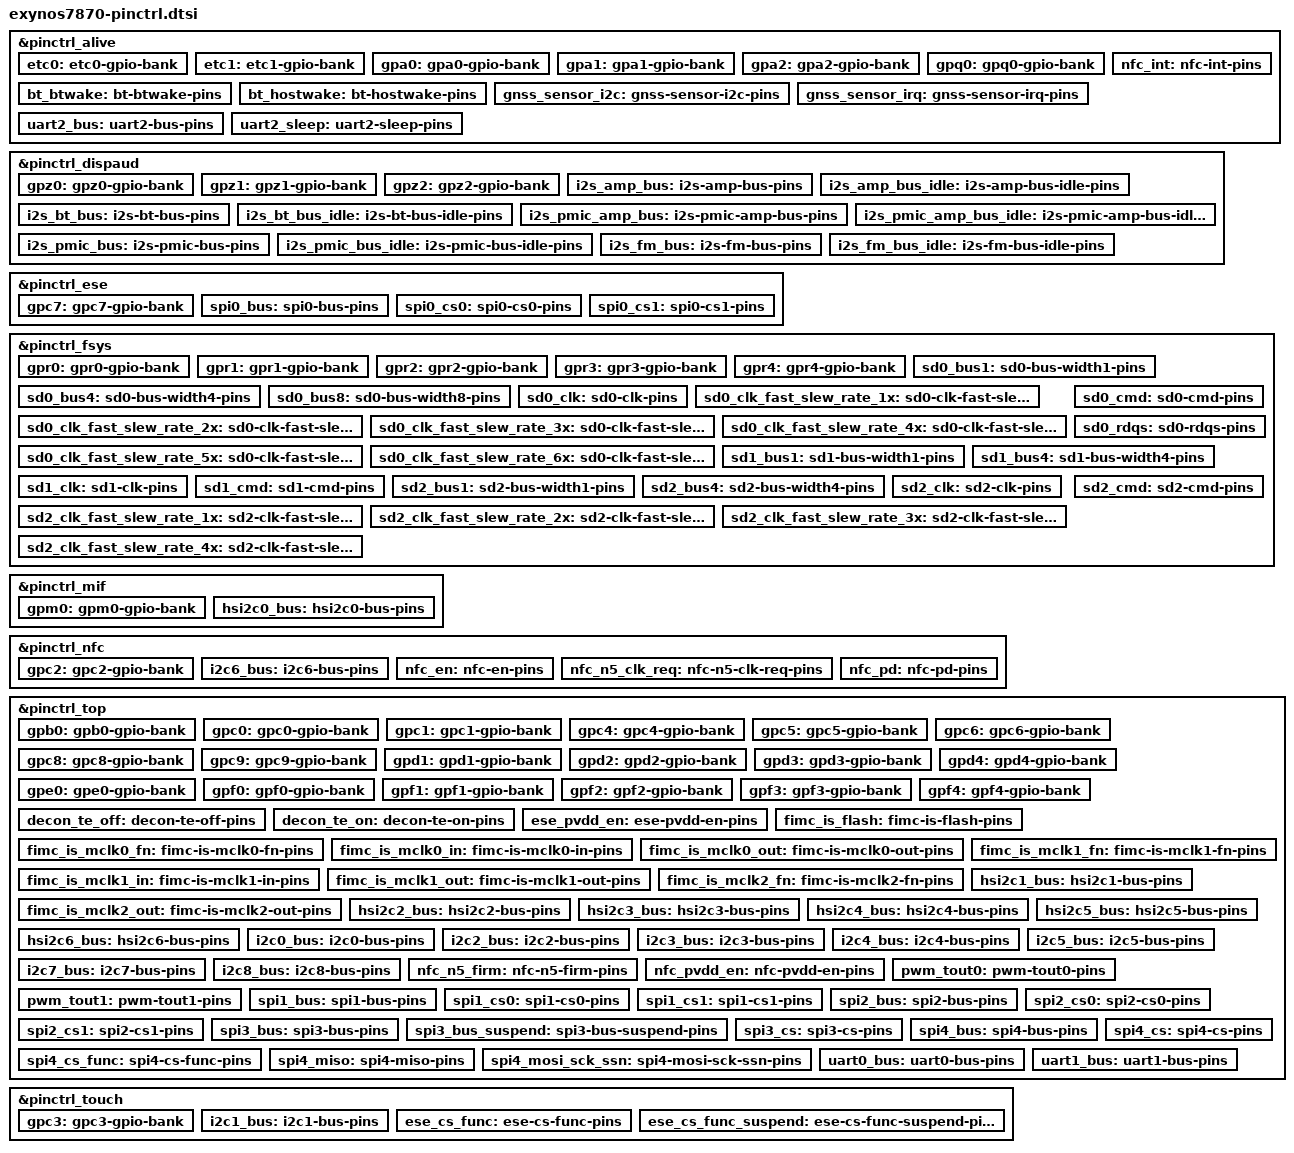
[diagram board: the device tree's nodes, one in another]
// SPDX-License-Identifier: GPL-2.0
/*
 * Samsung Exynos7870 SoC pin-mux and pin-config device tree source
 *
 * Copyright (c) 2015 Samsung Electronics Co., Ltd.
 * Copyright (c) 2025 Kaustabh Chakraborty <kauschluss@disroot.org>
 */

#include <dt-bindings/interrupt-controller/arm-gic.h>
#include "exynos-pinctrl.h"

&pinctrl_alive {
	etc0: etc0-gpio-bank {
		gpio-controller;
		#gpio-cells = <2>;

		interrupt-controller;
		#interrupt-cells = <2>;
	};

	etc1: etc1-gpio-bank {
		gpio-controller;
		#gpio-cells = <2>;

		interrupt-controller;
		#interrupt-cells = <2>;
	};

	gpa0: gpa0-gpio-bank {
		gpio-controller;
		#gpio-cells = <2>;

		interrupt-controller;
		#interrupt-cells = <2>;
		interrupt-parent = <&gic>;
		interrupts = <GIC_SPI 0 IRQ_TYPE_LEVEL_HIGH>,
			     <GIC_SPI 1 IRQ_TYPE_LEVEL_HIGH>,
			     <GIC_SPI 2 IRQ_TYPE_LEVEL_HIGH>,
			     <GIC_SPI 3 IRQ_TYPE_LEVEL_HIGH>,
			     <GIC_SPI 4 IRQ_TYPE_LEVEL_HIGH>,
			     <GIC_SPI 5 IRQ_TYPE_LEVEL_HIGH>,
			     <GIC_SPI 6 IRQ_TYPE_LEVEL_HIGH>,
			     <GIC_SPI 7 IRQ_TYPE_LEVEL_HIGH>;
	};

	gpa1: gpa1-gpio-bank {
		gpio-controller;
		#gpio-cells = <2>;

		interrupt-controller;
		#interrupt-cells = <2>;
		interrupt-parent = <&gic>;
		interrupts = <GIC_SPI 8 IRQ_TYPE_LEVEL_HIGH>,
			     <GIC_SPI 9 IRQ_TYPE_LEVEL_HIGH>,
			     <GIC_SPI 10 IRQ_TYPE_LEVEL_HIGH>,
			     <GIC_SPI 11 IRQ_TYPE_LEVEL_HIGH>,
			     <GIC_SPI 12 IRQ_TYPE_LEVEL_HIGH>,
			     <GIC_SPI 13 IRQ_TYPE_LEVEL_HIGH>,
			     <GIC_SPI 14 IRQ_TYPE_LEVEL_HIGH>,
			     <GIC_SPI 15 IRQ_TYPE_LEVEL_HIGH>;
	};

	gpa2: gpa2-gpio-bank {
		gpio-controller;
		#gpio-cells = <2>;

		interrupt-controller;
		#interrupt-cells = <2>;
	};

	gpq0: gpq0-gpio-bank {
		gpio-controller;
		#gpio-cells = <2>;

		interrupt-controller;
		#interrupt-cells = <2>;
	};

	bt_btwake: bt-btwake-pins {
		samsung,pins = "gpa1-2";
		samsung,pin-function = <EXYNOS_PIN_FUNC_OUTPUT>;
		samsung,pin-con-pdn = <EXYNOS_PIN_PDN_PREV>;
		samsung,pin-pud-pdn = <EXYNOS_PIN_PULL_NONE>;
		samsung,pin-pud = <EXYNOS_PIN_PULL_NONE>;
	};

	bt_hostwake: bt-hostwake-pins {
		samsung,pins = "gpa1-6";
		samsung,pin-function = <EXYNOS_PIN_FUNC_INPUT>;
		samsung,pin-con-pdn = <EXYNOS_PIN_PDN_INPUT>;
		samsung,pin-pud-pdn = <EXYNOS_PIN_PULL_NONE>;
		samsung,pin-pud = <EXYNOS_PIN_PULL_NONE>;
	};

	gnss_sensor_i2c: gnss-sensor-i2c-pins {
		samsung,pins = "gpa2-5", "gpa2-4";
		samsung,pin-function = <EXYNOS_PIN_FUNC_6>;
		samsung,pin-pud = <EXYNOS_PIN_PULL_NONE>;
	};

	gnss_sensor_irq: gnss-sensor-irq-pins {
		samsung,pins = "gpa2-3";
		samsung,pin-function = <EXYNOS_PIN_FUNC_6>;
		samsung,pin-pud = <EXYNOS_PIN_PULL_UP>;
	};

	nfc_int: nfc-int-pins {
		samsung,pins = "gpa2-6";
		samsung,pin-function = <EXYNOS_PIN_FUNC_INPUT>;
		samsung,pin-pud = <EXYNOS_PIN_PULL_DOWN>;
	};

	uart2_bus: uart2-bus-pins {
		samsung,pins = "gpa1-1", "gpa1-0";
		samsung,pin-function = <EXYNOS_PIN_FUNC_2>;
		samsung,pin-pud = <EXYNOS_PIN_PULL_NONE>;
	};

	uart2_sleep: uart2-sleep-pins {
		samsung,pins = "gpa1-1";
		samsung,pin-function = <EXYNOS_PIN_FUNC_INPUT>;
		samsung,pin-pud = <EXYNOS_PIN_PULL_DOWN>;
	};
};

&pinctrl_dispaud {
	gpz0: gpz0-gpio-bank {
		gpio-controller;
		#gpio-cells = <2>;

		interrupt-controller;
		#interrupt-cells = <2>;
	};

	gpz1: gpz1-gpio-bank {
		gpio-controller;
		#gpio-cells = <2>;

		interrupt-controller;
		#interrupt-cells = <2>;
	};

	gpz2: gpz2-gpio-bank {
		gpio-controller;
		#gpio-cells = <2>;

		interrupt-controller;
		#interrupt-cells = <2>;
	};

	i2s_amp_bus: i2s-amp-bus-pins {
		samsung,pins = "gpz1-5";
		samsung,pin-function = <EXYNOS_PIN_FUNC_2>;
		samsung,pin-pud = <EXYNOS_PIN_PULL_UP>;
		samsung,pin-drv = <EXYNOS5433_PIN_DRV_FAST_SR3>;
	};

	i2s_amp_bus_idle: i2s-amp-bus-idle-pins {
		samsung,pins = "gpz1-5";
		samsung,pin-function = <EXYNOS_PIN_FUNC_INPUT>;
		samsung,pin-pud = <EXYNOS_PIN_PULL_UP>;
		samsung,pin-drv = <EXYNOS5433_PIN_DRV_FAST_SR3>;
	};

	i2s_bt_bus: i2s-bt-bus-pins {
		samsung,pins = "gpz0-0", "gpz0-1", "gpz0-2", "gpz0-3";
		samsung,pin-function = <EXYNOS_PIN_FUNC_2>;
		samsung,pin-pud = <EXYNOS_PIN_PULL_UP>;
		samsung,pin-drv = <EXYNOS5433_PIN_DRV_FAST_SR3>;
	};

	i2s_bt_bus_idle: i2s-bt-bus-idle-pins {
		samsung,pins = "gpz0-0", "gpz0-1", "gpz0-2", "gpz0-3";
		samsung,pin-function = <EXYNOS_PIN_FUNC_INPUT>;
		samsung,pin-pud = <EXYNOS_PIN_PULL_UP>;
		samsung,pin-drv = <EXYNOS5433_PIN_DRV_FAST_SR3>;
	};

	i2s_pmic_amp_bus: i2s-pmic-amp-bus-pins {
		samsung,pins = "gpz1-0", "gpz1-1", "gpz1-2", "gpz1-3", "gpz1-4";
		samsung,pin-function = <EXYNOS_PIN_FUNC_2>;
		samsung,pin-pud = <EXYNOS_PIN_PULL_UP>;
		samsung,pin-drv = <EXYNOS5433_PIN_DRV_FAST_SR6>;
	};

	i2s_pmic_amp_bus_idle: i2s-pmic-amp-bus-idle-pins {
		samsung,pins = "gpz1-0", "gpz1-1", "gpz1-2", "gpz1-3", "gpz1-4";
		samsung,pin-function = <EXYNOS_PIN_FUNC_INPUT>;
		samsung,pin-pud = <EXYNOS_PIN_PULL_UP>;
		samsung,pin-drv = <EXYNOS5433_PIN_DRV_FAST_SR6>;
	};

	i2s_pmic_bus: i2s-pmic-bus-pins {
		samsung,pins = "gpz1-0", "gpz1-2", "gpz1-3", "gpz1-4";
		samsung,pin-function = <EXYNOS_PIN_FUNC_2>;
		samsung,pin-pud = <EXYNOS_PIN_PULL_UP>;
		samsung,pin-drv = <EXYNOS5433_PIN_DRV_FAST_SR6>;
	};

	i2s_pmic_bus_idle: i2s-pmic-bus-idle-pins {
		samsung,pins = "gpz1-0", "gpz1-2", "gpz1-3", "gpz1-4";
		samsung,pin-function = <EXYNOS_PIN_FUNC_INPUT>;
		samsung,pin-pud = <EXYNOS_PIN_PULL_UP>;
		samsung,pin-drv = <EXYNOS5433_PIN_DRV_FAST_SR6>;
	};

	i2s_fm_bus: i2s-fm-bus-pins {
		samsung,pins = "gpz2-0", "gpz2-1", "gpz2-2", "gpz2-3";
		samsung,pin-function = <EXYNOS_PIN_FUNC_2>;
		samsung,pin-pud = <EXYNOS_PIN_PULL_NONE>;
		samsung,pin-drv = <EXYNOS5433_PIN_DRV_FAST_SR3>;
	};

	i2s_fm_bus_idle: i2s-fm-bus-idle-pins {
		samsung,pins = "gpz2-0", "gpz2-1", "gpz2-2", "gpz2-3";
		samsung,pin-function = <EXYNOS_PIN_FUNC_INPUT>;
		samsung,pin-pud = <EXYNOS_PIN_PULL_NONE>;
		samsung,pin-drv = <EXYNOS5433_PIN_DRV_FAST_SR3>;
	};
};

&pinctrl_ese {
	gpc7: gpc7-gpio-bank {
		gpio-controller;
		#gpio-cells = <2>;

		interrupt-controller;
		#interrupt-cells = <2>;
	};

	spi0_bus: spi0-bus-pins {
		samsung,pins = "gpc7-3", "gpc7-2", "gpc7-0";
		samsung,pin-function = <EXYNOS_PIN_FUNC_2>;
		samsung,pin-pud = <EXYNOS_PIN_PULL_UP>;
		samsung,pin-drv = <EXYNOS5433_PIN_DRV_FAST_SR3>;
	};

	spi0_cs0: spi0-cs0-pins {
		samsung,pins = "gpc7-1";
		samsung,pin-function = <EXYNOS_PIN_FUNC_OUTPUT>;
		samsung,pin-pud = <EXYNOS_PIN_PULL_UP>;
		samsung,pin-drv = <EXYNOS5433_PIN_DRV_FAST_SR3>;
	};

	spi0_cs1: spi0-cs1-pins {
		samsung,pins = "gpc7-4";
		samsung,pin-function = <EXYNOS_PIN_FUNC_OUTPUT>;
		samsung,pin-pud = <EXYNOS_PIN_PULL_UP>;
		samsung,pin-drv = <EXYNOS5433_PIN_DRV_FAST_SR1>;
	};
};

&pinctrl_fsys {
	gpr0: gpr0-gpio-bank {
		gpio-controller;
		#gpio-cells = <2>;

		interrupt-controller;
		#interrupt-cells = <2>;
	};

	gpr1: gpr1-gpio-bank {
		gpio-controller;
		#gpio-cells = <2>;

		interrupt-controller;
		#interrupt-cells = <2>;
	};

	gpr2: gpr2-gpio-bank {
		gpio-controller;
		#gpio-cells = <2>;

		interrupt-controller;
		#interrupt-cells = <2>;
	};

	gpr3: gpr3-gpio-bank {
		gpio-controller;
		#gpio-cells = <2>;

		interrupt-controller;
		#interrupt-cells = <2>;
	};

	gpr4: gpr4-gpio-bank {
		gpio-controller;
		#gpio-cells = <2>;

		interrupt-controller;
		#interrupt-cells = <2>;
		interrupt-parent = <&gic>;
		interrupts = <GIC_SPI 0 IRQ_TYPE_LEVEL_HIGH>,
			     <GIC_SPI 1 IRQ_TYPE_LEVEL_HIGH>,
			     <GIC_SPI 2 IRQ_TYPE_LEVEL_HIGH>,
			     <GIC_SPI 3 IRQ_TYPE_LEVEL_HIGH>,
			     <GIC_SPI 4 IRQ_TYPE_LEVEL_HIGH>,
			     <GIC_SPI 5 IRQ_TYPE_LEVEL_HIGH>;
	};

	sd0_bus1: sd0-bus-width1-pins {
		samsung,pins = "gpr1-0";
		samsung,pin-function = <EXYNOS_PIN_FUNC_2>;
		samsung,pin-pud = <EXYNOS_PIN_PULL_UP>;
		samsung,pin-drv = <EXYNOS5433_PIN_DRV_FAST_SR3>;
	};

	sd0_bus4: sd0-bus-width4-pins {
		samsung,pins = "gpr1-1", "gpr1-2", "gpr1-3";
		samsung,pin-function = <EXYNOS_PIN_FUNC_2>;
		samsung,pin-pud = <EXYNOS_PIN_PULL_UP>;
		samsung,pin-drv = <EXYNOS5433_PIN_DRV_FAST_SR3>;
	};

	sd0_bus8: sd0-bus-width8-pins {
		samsung,pins = "gpr1-4", "gpr1-5", "gpr1-6", "gpr1-7";
		samsung,pin-function = <EXYNOS_PIN_FUNC_2>;
		samsung,pin-pud = <EXYNOS_PIN_PULL_UP>;
		samsung,pin-drv = <EXYNOS5433_PIN_DRV_FAST_SR3>;
	};

	sd0_clk: sd0-clk-pins {
		samsung,pins = "gpr0-0";
		samsung,pin-function = <EXYNOS_PIN_FUNC_2>;
		samsung,pin-pud = <EXYNOS_PIN_PULL_NONE>;
		samsung,pin-drv = <EXYNOS5433_PIN_DRV_FAST_SR3>;
	};

	sd0_clk_fast_slew_rate_1x: sd0-clk-fast-slew-rate-1x-pins {
		samsung,pins = "gpr0-0";
		samsung,pin-function = <EXYNOS_PIN_FUNC_2>;
		samsung,pin-pud = <EXYNOS_PIN_PULL_NONE>;
		samsung,pin-drv = <EXYNOS5433_PIN_DRV_FAST_SR1>;
	};

	sd0_clk_fast_slew_rate_2x: sd0-clk-fast-slew-rate-2x-pins {
		samsung,pins = "gpr0-0";
		samsung,pin-function = <EXYNOS_PIN_FUNC_2>;
		samsung,pin-pud = <EXYNOS_PIN_PULL_NONE>;
		samsung,pin-drv = <EXYNOS5433_PIN_DRV_FAST_SR2>;
	};

	sd0_clk_fast_slew_rate_3x: sd0-clk-fast-slew-rate-3x-pins {
		samsung,pins = "gpr0-0";
		samsung,pin-function = <EXYNOS_PIN_FUNC_2>;
		samsung,pin-pud = <EXYNOS_PIN_PULL_NONE>;
		samsung,pin-drv = <EXYNOS5433_PIN_DRV_FAST_SR3>;
	};

	sd0_clk_fast_slew_rate_4x: sd0-clk-fast-slew-rate-4x-pins {
		samsung,pins = "gpr0-0";
		samsung,pin-function = <EXYNOS_PIN_FUNC_2>;
		samsung,pin-pud = <EXYNOS_PIN_PULL_NONE>;
		samsung,pin-drv = <EXYNOS5433_PIN_DRV_FAST_SR4>;
	};

	sd0_clk_fast_slew_rate_5x: sd0-clk-fast-slew-rate-5x-pins {
		samsung,pins = "gpr0-0";
		samsung,pin-function = <EXYNOS_PIN_FUNC_2>;
		samsung,pin-pud = <EXYNOS_PIN_PULL_NONE>;
		samsung,pin-drv = <EXYNOS5433_PIN_DRV_FAST_SR5>;
	};

	sd0_clk_fast_slew_rate_6x: sd0-clk-fast-slew-rate-6x-pins {
		samsung,pins = "gpr0-0";
		samsung,pin-function = <EXYNOS_PIN_FUNC_2>;
		samsung,pin-pud = <EXYNOS_PIN_PULL_NONE>;
		samsung,pin-drv = <EXYNOS5433_PIN_DRV_FAST_SR6>;
	};

	sd0_cmd: sd0-cmd-pins {
		samsung,pins = "gpr0-1";
		samsung,pin-function = <EXYNOS_PIN_FUNC_2>;
		samsung,pin-pud = <EXYNOS_PIN_PULL_UP>;
		samsung,pin-drv = <EXYNOS5433_PIN_DRV_FAST_SR3>;
	};

	sd0_rdqs: sd0-rdqs-pins {
		samsung,pins = "gpr0-2";
		samsung,pin-function = <EXYNOS_PIN_FUNC_2>;
		samsung,pin-pud = <EXYNOS_PIN_PULL_NONE>;
		samsung,pin-drv = <EXYNOS5433_PIN_DRV_FAST_SR3>;
	};

	sd1_bus1: sd1-bus-width1-pins {
		samsung,pins = "gpr3-0";
		samsung,pin-function = <EXYNOS_PIN_FUNC_2>;
		samsung,pin-con-pdn = <EXYNOS_PIN_PDN_INPUT>;
		samsung,pin-pud-pdn = <EXYNOS_PIN_PULL_UP>;
		samsung,pin-pud = <EXYNOS_PIN_PULL_UP>;
		samsung,pin-drv = <EXYNOS5433_PIN_DRV_FAST_SR3>;
	};

	sd1_bus4: sd1-bus-width4-pins {
		samsung,pins = "gpr3-1", "gpr3-2", "gpr3-3";
		samsung,pin-function = <EXYNOS_PIN_FUNC_2>;
		samsung,pin-con-pdn = <EXYNOS_PIN_PDN_INPUT>;
		samsung,pin-pud-pdn = <EXYNOS_PIN_PULL_UP>;
		samsung,pin-pud = <EXYNOS_PIN_PULL_UP>;
		samsung,pin-drv = <EXYNOS5433_PIN_DRV_FAST_SR3>;
	};

	sd1_clk: sd1-clk-pins {
		samsung,pins = "gpr2-0";
		samsung,pin-function = <EXYNOS_PIN_FUNC_2>;
		samsung,pin-pud = <EXYNOS_PIN_PULL_NONE>;
		samsung,pin-drv = <EXYNOS5433_PIN_DRV_FAST_SR3>;
	};

	sd1_cmd: sd1-cmd-pins {
		samsung,pins = "gpr2-1";
		samsung,pin-function = <EXYNOS_PIN_FUNC_2>;
		samsung,pin-pud = <EXYNOS_PIN_PULL_UP>;
		samsung,pin-drv = <EXYNOS5433_PIN_DRV_FAST_SR3>;
	};

	sd2_bus1: sd2-bus-width1-pins {
		samsung,pins = "gpr4-2";
		samsung,pin-function = <EXYNOS_PIN_FUNC_2>;
		samsung,pin-pud = <EXYNOS_PIN_PULL_UP>;
		samsung,pin-drv = <EXYNOS5433_PIN_DRV_FAST_SR3>;
	};

	sd2_bus4: sd2-bus-width4-pins {
		samsung,pins = "gpr4-3", "gpr4-4", "gpr4-5";
		samsung,pin-function = <EXYNOS_PIN_FUNC_2>;
		samsung,pin-pud = <EXYNOS_PIN_PULL_UP>;
		samsung,pin-drv = <EXYNOS5433_PIN_DRV_FAST_SR3>;
	};

	sd2_clk: sd2-clk-pins {
		samsung,pins = "gpr4-0";
		samsung,pin-function = <EXYNOS_PIN_FUNC_2>;
		samsung,pin-pud = <EXYNOS_PIN_PULL_NONE>;
		samsung,pin-drv = <EXYNOS5433_PIN_DRV_FAST_SR3>;
	};

	sd2_clk_fast_slew_rate_1x: sd2-clk-fast-slew-rate-1x-pins {
		samsung,pins = "gpr4-0";
		samsung,pin-function = <EXYNOS_PIN_FUNC_2>;
		samsung,pin-pud = <EXYNOS_PIN_PULL_NONE>;
		samsung,pin-drv = <EXYNOS5433_PIN_DRV_FAST_SR1>;
	};

	sd2_clk_fast_slew_rate_2x: sd2-clk-fast-slew-rate-2x-pins {
		samsung,pins = "gpr4-0";
		samsung,pin-function = <EXYNOS_PIN_FUNC_2>;
		samsung,pin-pud = <EXYNOS_PIN_PULL_NONE>;
		samsung,pin-drv = <EXYNOS5433_PIN_DRV_FAST_SR2>;
	};

	sd2_clk_fast_slew_rate_3x: sd2-clk-fast-slew-rate-3x-pins {
		samsung,pins = "gpr4-0";
		samsung,pin-function = <EXYNOS_PIN_FUNC_2>;
		samsung,pin-pud = <EXYNOS_PIN_PULL_NONE>;
		samsung,pin-drv = <EXYNOS5433_PIN_DRV_FAST_SR3>;
	};

	sd2_clk_fast_slew_rate_4x: sd2-clk-fast-slew-rate-4x-pins {
		samsung,pins = "gpr4-0";
		samsung,pin-function = <EXYNOS_PIN_FUNC_2>;
		samsung,pin-pud = <EXYNOS_PIN_PULL_NONE>;
		samsung,pin-drv = <EXYNOS5433_PIN_DRV_FAST_SR4>;
	};

	sd2_cmd: sd2-cmd-pins {
		samsung,pins = "gpr4-1";
		samsung,pin-function = <EXYNOS_PIN_FUNC_2>;
		samsung,pin-pud = <EXYNOS_PIN_PULL_UP>;
		samsung,pin-drv = <EXYNOS5433_PIN_DRV_FAST_SR3>;
	};
};

&pinctrl_mif {
	gpm0: gpm0-gpio-bank {
		gpio-controller;
		#gpio-cells = <2>;

		interrupt-controller;
		#interrupt-cells = <2>;
	};

	hsi2c0_bus: hsi2c0-bus-pins {
		samsung,pins = "gpm0-1", "gpm0-0";
		samsung,pin-function = <EXYNOS_PIN_FUNC_2>;
		samsung,pin-con-pdn = <EXYNOS_PIN_PDN_PREV>;
		samsung,pin-pud = <EXYNOS_PIN_PULL_NONE>;
		samsung,pin-drv = <EXYNOS5433_PIN_DRV_FAST_SR1>;
	};
};

&pinctrl_nfc {
	gpc2: gpc2-gpio-bank {
		gpio-controller;
		#gpio-cells = <2>;

		interrupt-controller;
		#interrupt-cells = <2>;
	};

	i2c6_bus: i2c6-bus-pins {
		samsung,pins = "gpc2-1", "gpc2-0";
		samsung,pin-function = <EXYNOS_PIN_FUNC_2>;
		samsung,pin-pud = <EXYNOS_PIN_PULL_NONE>;
		samsung,pin-drv = <EXYNOS5433_PIN_DRV_FAST_SR1>;
	};

	nfc_en: nfc-en-pins {
		samsung,pins = "gpc2-2";
		samsung,pin-function = <EXYNOS_PIN_FUNC_OUTPUT>;
		samsung,pin-con-pdn = <EXYNOS_PIN_PDN_PREV>;
		samsung,pin-pud = <EXYNOS_PIN_PULL_NONE>;
		samsung,pin-drv = <EXYNOS5433_PIN_DRV_FAST_SR1>;
		samsung,pin-val = <1>;
	};

	nfc_n5_clk_req: nfc-n5-clk-req-pins {
		samsung,pins = "gpc2-3";
		samsung,pin-function = <EXYNOS_PIN_FUNC_2>;
		samsung,pin-pud = <EXYNOS_PIN_PULL_UP>;
		samsung,pin-drv = <EXYNOS5433_PIN_DRV_FAST_SR1>;
	};

	nfc_pd: nfc-pd-pins {
		samsung,pins = "gpc2-2";
		samsung,pin-function = <EXYNOS_PIN_FUNC_2>;
		samsung,pin-pud = <EXYNOS_PIN_PULL_UP>;
		samsung,pin-drv = <EXYNOS5433_PIN_DRV_FAST_SR1>;
	};
};

&pinctrl_top {
	gpb0: gpb0-gpio-bank {
		gpio-controller;
		#gpio-cells = <2>;

		interrupt-controller;
		#interrupt-cells = <2>;
	};

	gpc0: gpc0-gpio-bank {
		gpio-controller;
		#gpio-cells = <2>;

		interrupt-controller;
		#interrupt-cells = <2>;
	};

	gpc1: gpc1-gpio-bank {
		gpio-controller;
		#gpio-cells = <2>;

		interrupt-controller;
		#interrupt-cells = <2>;
	};

	gpc4: gpc4-gpio-bank {
		gpio-controller;
		#gpio-cells = <2>;

		interrupt-controller;
		#interrupt-cells = <2>;
	};

	gpc5: gpc5-gpio-bank {
		gpio-controller;
		#gpio-cells = <2>;

		interrupt-controller;
		#interrupt-cells = <2>;
	};

	gpc6: gpc6-gpio-bank {
		gpio-controller;
		#gpio-cells = <2>;

		interrupt-controller;
		#interrupt-cells = <2>;
	};

	gpc8: gpc8-gpio-bank {
		gpio-controller;
		#gpio-cells = <2>;

		interrupt-controller;
		#interrupt-cells = <2>;
	};

	gpc9: gpc9-gpio-bank {
		gpio-controller;
		#gpio-cells = <2>;

		interrupt-controller;
		#interrupt-cells = <2>;
	};

	gpd1: gpd1-gpio-bank {
		gpio-controller;
		#gpio-cells = <2>;

		interrupt-controller;
		#interrupt-cells = <2>;
	};

	gpd2: gpd2-gpio-bank {
		gpio-controller;
		#gpio-cells = <2>;

		interrupt-controller;
		#interrupt-cells = <2>;
	};

	gpd3: gpd3-gpio-bank {
		gpio-controller;
		#gpio-cells = <2>;

		interrupt-controller;
		#interrupt-cells = <2>;
	};

	gpd4: gpd4-gpio-bank {
		gpio-controller;
		#gpio-cells = <2>;

		interrupt-controller;
		#interrupt-cells = <2>;
	};

	gpe0: gpe0-gpio-bank {
		gpio-controller;
		#gpio-cells = <2>;

		interrupt-controller;
		#interrupt-cells = <2>;
	};

	gpf0: gpf0-gpio-bank {
		gpio-controller;
		#gpio-cells = <2>;

		interrupt-controller;
		#interrupt-cells = <2>;
	};

	gpf1: gpf1-gpio-bank {
		gpio-controller;
		#gpio-cells = <2>;

		interrupt-controller;
		#interrupt-cells = <2>;
	};

	gpf2: gpf2-gpio-bank {
		gpio-controller;
		#gpio-cells = <2>;

		interrupt-controller;
		#interrupt-cells = <2>;
	};

	gpf3: gpf3-gpio-bank {
		gpio-controller;
		#gpio-cells = <2>;

		interrupt-controller;
		#interrupt-cells = <2>;
	};

	gpf4: gpf4-gpio-bank {
		gpio-controller;
		#gpio-cells = <2>;

		interrupt-controller;
		#interrupt-cells = <2>;
	};

	decon_te_off: decon-te-off-pins {
		samsung,pins = "gpe0-2";
		samsung,pin-function = <EXYNOS_PIN_FUNC_INPUT>;
	};

	decon_te_on: decon-te-on-pins {
		samsung,pins = "gpe0-2";
		samsung,pin-function = <EXYNOS_PIN_FUNC_2>;
	};

	ese_pvdd_en: ese-pvdd-en-pins {
		samsung,pins = "gpf4-0";
		samsung,pin-function = <EXYNOS_PIN_FUNC_OUTPUT>;
		samsung,pin-pud = <EXYNOS_PIN_PULL_DOWN>;
		samsung,pin-drv = <EXYNOS5433_PIN_DRV_FAST_SR4>;
	};

	fimc_is_flash: fimc-is-flash-pins {
		samsung,pins = "gpd3-2", "gpd3-3";
		samsung,pin-function = <EXYNOS_PIN_FUNC_OUTPUT>;
		samsung,pin-pud = <EXYNOS_PIN_PULL_NONE>;
		samsung,pin-drv = <EXYNOS5433_PIN_DRV_FAST_SR1>;
	};

	fimc_is_mclk0_fn: fimc-is-mclk0-fn-pins {
		samsung,pins = "gpe0-0";
		samsung,pin-function = <EXYNOS_PIN_FUNC_2>;
		samsung,pin-pud = <EXYNOS_PIN_PULL_NONE>;
		samsung,pin-drv = <EXYNOS5433_PIN_DRV_FAST_SR2>;
	};

	fimc_is_mclk0_in: fimc-is-mclk0-in-pins {
		samsung,pins = "gpe0-0";
		samsung,pin-function = <EXYNOS_PIN_FUNC_INPUT>;
		samsung,pin-pud = <EXYNOS_PIN_PULL_NONE>;
		samsung,pin-drv = <EXYNOS5433_PIN_DRV_FAST_SR1>;
	};

	fimc_is_mclk0_out: fimc-is-mclk0-out-pins {
		samsung,pins = "gpe0-0";
		samsung,pin-function = <EXYNOS_PIN_FUNC_OUTPUT>;
		samsung,pin-pud = <EXYNOS_PIN_PULL_DOWN>;
		samsung,pin-drv = <EXYNOS5433_PIN_DRV_FAST_SR3>;
	};

	fimc_is_mclk1_fn: fimc-is-mclk1-fn-pins {
		samsung,pins = "gpe0-1";
		samsung,pin-function = <EXYNOS_PIN_FUNC_2>;
		samsung,pin-pud = <EXYNOS_PIN_PULL_NONE>;
		samsung,pin-drv = <EXYNOS5433_PIN_DRV_FAST_SR2>;
	};

	fimc_is_mclk1_in: fimc-is-mclk1-in-pins {
		samsung,pins = "gpe0-1";
		samsung,pin-function = <EXYNOS_PIN_FUNC_INPUT>;
		samsung,pin-pud = <EXYNOS_PIN_PULL_NONE>;
		samsung,pin-drv = <EXYNOS5433_PIN_DRV_FAST_SR1>;
	};

	fimc_is_mclk1_out: fimc-is-mclk1-out-pins {
		samsung,pins = "gpe0-1";
		samsung,pin-function = <EXYNOS_PIN_FUNC_OUTPUT>;
		samsung,pin-pud = <EXYNOS_PIN_PULL_DOWN>;
		samsung,pin-drv = <EXYNOS5433_PIN_DRV_FAST_SR3>;
	};

	fimc_is_mclk2_fn: fimc-is-mclk2-fn-pins {
		samsung,pins = "gpf4-4";
		samsung,pin-function = <EXYNOS_PIN_FUNC_2>;
		samsung,pin-pud = <EXYNOS_PIN_PULL_NONE>;
		samsung,pin-drv = <EXYNOS5433_PIN_DRV_FAST_SR3>;
	};

	fimc_is_mclk2_out: fimc-is-mclk2-out-pins {
		samsung,pins = "gpf4-4";
		samsung,pin-function = <EXYNOS_PIN_FUNC_OUTPUT>;
		samsung,pin-pud = <EXYNOS_PIN_PULL_NONE>;
		samsung,pin-drv = <EXYNOS5433_PIN_DRV_FAST_SR3>;
		samsung,pin-val = <0>;
	};

	hsi2c1_bus: hsi2c1-bus-pins {
		samsung,pins = "gpf0-1", "gpf0-0";
		samsung,pin-function = <EXYNOS_PIN_FUNC_2>;
		samsung,pin-pud = <EXYNOS_PIN_PULL_NONE>;
		samsung,pin-drv = <EXYNOS5433_PIN_DRV_FAST_SR1>;
	};

	hsi2c2_bus: hsi2c2-bus-pins {
		samsung,pins = "gpf1-1", "gpf1-0";
		samsung,pin-function = <EXYNOS_PIN_FUNC_2>;
		samsung,pin-pud = <EXYNOS_PIN_PULL_NONE>;
		samsung,pin-drv = <EXYNOS5433_PIN_DRV_FAST_SR1>;
	};

	hsi2c3_bus: hsi2c3-bus-pins {
		samsung,pins = "gpf0-3", "gpf0-2";
		samsung,pin-function = <EXYNOS_PIN_FUNC_2>;
		samsung,pin-pud = <EXYNOS_PIN_PULL_NONE>;
		samsung,pin-drv = <EXYNOS5433_PIN_DRV_FAST_SR1>;
	};

	hsi2c4_bus: hsi2c4-bus-pins {
		samsung,pins = "gpf2-1", "gpf2-0";
		samsung,pin-function = <EXYNOS_PIN_FUNC_2>;
		samsung,pin-pud = <EXYNOS_PIN_PULL_NONE>;
		samsung,pin-drv = <EXYNOS5433_PIN_DRV_FAST_SR1>;
	};

	hsi2c5_bus: hsi2c5-bus-pins {
		samsung,pins = "gpf3-0", "gpf3-1";
		samsung,pin-function = <EXYNOS_PIN_FUNC_3>;
		samsung,pin-pud = <EXYNOS_PIN_PULL_NONE>;
		samsung,pin-drv = <EXYNOS5433_PIN_DRV_FAST_SR1>;
	};

	hsi2c6_bus: hsi2c6-bus-pins {
		samsung,pins = "gpf3-2", "gpf3-3";
		samsung,pin-function = <EXYNOS_PIN_FUNC_3>;
		samsung,pin-pud = <EXYNOS_PIN_PULL_NONE>;
		samsung,pin-drv = <EXYNOS5433_PIN_DRV_FAST_SR1>;
	};

	i2c0_bus: i2c0-bus-pins {
		samsung,pins = "gpc4-1", "gpc4-0";
		samsung,pin-function = <EXYNOS_PIN_FUNC_2>;
		samsung,pin-pud = <EXYNOS_PIN_PULL_UP>;
		samsung,pin-drv = <EXYNOS5433_PIN_DRV_FAST_SR1>;
	};

	i2c2_bus: i2c2-bus-pins {
		samsung,pins = "gpc8-1", "gpc8-0";
		samsung,pin-function = <EXYNOS_PIN_FUNC_2>;
		samsung,pin-pud = <EXYNOS_PIN_PULL_NONE>;
		samsung,pin-drv = <EXYNOS5433_PIN_DRV_FAST_SR1>;
	};

	i2c3_bus: i2c3-bus-pins {
		samsung,pins = "gpc9-1", "gpc9-0";
		samsung,pin-function = <EXYNOS_PIN_FUNC_2>;
		samsung,pin-pud = <EXYNOS_PIN_PULL_NONE>;
		samsung,pin-drv = <EXYNOS5433_PIN_DRV_FAST_SR1>;
	};

	i2c4_bus: i2c4-bus-pins {
		samsung,pins = "gpc1-1", "gpc1-0";
		samsung,pin-function = <EXYNOS_PIN_FUNC_2>;
		samsung,pin-con-pdn = <EXYNOS_PIN_PDN_PREV>;
		samsung,pin-pud-pdn = <EXYNOS_PIN_PULL_UP>;
		samsung,pin-pud = <EXYNOS_PIN_PULL_UP>;
		samsung,pin-drv = <EXYNOS5433_PIN_DRV_FAST_SR1>;
	};

	i2c5_bus: i2c5-bus-pins {
		samsung,pins = "gpc1-3", "gpc1-2";
		samsung,pin-function = <EXYNOS_PIN_FUNC_2>;
		samsung,pin-pud = <EXYNOS_PIN_PULL_UP>;
		samsung,pin-drv = <EXYNOS5433_PIN_DRV_FAST_SR1>;
	};

	i2c7_bus: i2c7-bus-pins {
		samsung,pins = "gpc4-3", "gpc4-2";
		samsung,pin-function = <EXYNOS_PIN_FUNC_2>;
		samsung,pin-pud = <EXYNOS_PIN_PULL_UP>;
		samsung,pin-drv = <EXYNOS5433_PIN_DRV_FAST_SR1>;
	};

	i2c8_bus: i2c8-bus-pins {
		samsung,pins = "gpc5-1", "gpc5-0";
		samsung,pin-function = <EXYNOS_PIN_FUNC_2>;
		samsung,pin-pud = <EXYNOS_PIN_PULL_UP>;
		samsung,pin-drv = <EXYNOS5433_PIN_DRV_FAST_SR1>;
	};

	nfc_n5_firm: nfc-n5-firm-pins {
		samsung,pins = "gpd4-1";
		samsung,pin-function = <EXYNOS_PIN_FUNC_OUTPUT>;
		samsung,pin-pud = <EXYNOS_PIN_PULL_DOWN>;
		samsung,pin-val = <1>;
	};

	nfc_pvdd_en: nfc-pvdd-en-pins {
		samsung,pins = "gpd2-1";
		samsung,pin-function = <EXYNOS_PIN_FUNC_OUTPUT>;
		samsung,pin-pud = <EXYNOS_PIN_PULL_UP>;
		samsung,pin-drv = <EXYNOS5433_PIN_DRV_FAST_SR4>;
	};

	pwm_tout0: pwm-tout0-pins {
		samsung,pins = "gpc0-1";
		samsung,pin-function = <EXYNOS_PIN_FUNC_2>;
		samsung,pin-pud = <EXYNOS_PIN_PULL_DOWN>;
		samsung,pin-drv = <EXYNOS5433_PIN_DRV_FAST_SR1>;
	};

	pwm_tout1: pwm-tout1-pins {
		samsung,pins = "gpc0-2";
		samsung,pin-function = <EXYNOS_PIN_FUNC_2>;
		samsung,pin-pud = <EXYNOS_PIN_PULL_DOWN>;
		samsung,pin-drv = <EXYNOS5433_PIN_DRV_FAST_SR1>;
	};

	spi1_bus: spi1-bus-pins {
		samsung,pins = "gpf3-3", "gpf3-2", "gpf3-0";
		samsung,pin-function = <EXYNOS_PIN_FUNC_2>;
		samsung,pin-pud = <EXYNOS_PIN_PULL_UP>;
		samsung,pin-drv = <EXYNOS5433_PIN_DRV_FAST_SR1>;
	};

	spi1_cs0: spi1-cs0-pins {
		samsung,pins = "gpf3-1";
		samsung,pin-function = <EXYNOS_PIN_FUNC_OUTPUT>;
		samsung,pin-pud = <EXYNOS_PIN_PULL_UP>;
		samsung,pin-drv = <EXYNOS5433_PIN_DRV_FAST_SR1>;
	};

	spi1_cs1: spi1-cs1-pins {
		samsung,pins = "gpd1-0";
		samsung,pin-function = <EXYNOS_PIN_FUNC_OUTPUT>;
		samsung,pin-pud = <EXYNOS_PIN_PULL_UP>;
		samsung,pin-drv = <EXYNOS5433_PIN_DRV_FAST_SR1>;
	};

	spi2_bus: spi2-bus-pins {
		samsung,pins = "gpf4-3", "gpf4-2", "gpf4-0";
		samsung,pin-function = <EXYNOS_PIN_FUNC_2>;
		samsung,pin-pud = <EXYNOS_PIN_PULL_UP>;
		samsung,pin-drv = <EXYNOS5433_PIN_DRV_FAST_SR1>;
	};

	spi2_cs0: spi2-cs0-pins {
		samsung,pins = "gpf4-1";
		samsung,pin-function = <EXYNOS_PIN_FUNC_OUTPUT>;
		samsung,pin-pud = <EXYNOS_PIN_PULL_UP>;
		samsung,pin-drv = <EXYNOS5433_PIN_DRV_FAST_SR1>;
	};

	spi2_cs1: spi2-cs1-pins {
		samsung,pins = "gpd1-1";
		samsung,pin-function = <EXYNOS_PIN_FUNC_OUTPUT>;
		samsung,pin-pud = <EXYNOS_PIN_PULL_UP>;
		samsung,pin-drv = <EXYNOS5433_PIN_DRV_FAST_SR1>;
	};

	spi3_bus: spi3-bus-pins {
		samsung,pins = "gpc6-0", "gpc6-2", "gpc6-3";
		samsung,pin-function = <EXYNOS_PIN_FUNC_2>;
		samsung,pin-pud = <EXYNOS_PIN_PULL_UP>;
		samsung,pin-drv = <EXYNOS5433_PIN_DRV_FAST_SR1>;
	};

	spi3_bus_suspend: spi3-bus-suspend-pins {
		samsung,pins = "gpc6-0", "gpc6-2", "gpc6-3";
		samsung,pin-function = <EXYNOS_PIN_FUNC_INPUT>;
		samsung,pin-pud = <EXYNOS_PIN_PULL_DOWN>;
		samsung,pin-drv = <EXYNOS5433_PIN_DRV_FAST_SR1>;
	};

	spi3_cs: spi3-cs-pins {
		samsung,pins = "gpc6-1";
		samsung,pin-function = <EXYNOS_PIN_FUNC_OUTPUT>;
		samsung,pin-pud = <EXYNOS_PIN_PULL_UP>;
		samsung,pin-drv = <EXYNOS5433_PIN_DRV_FAST_SR1>;
	};

	spi4_bus: spi4-bus-pins {
		samsung,pins = "gpc4-2", "gpc5-0", "gpc5-1";
		samsung,pin-function = <EXYNOS_PIN_FUNC_3>;
		samsung,pin-pud = <EXYNOS_PIN_PULL_UP>;
		samsung,pin-drv = <EXYNOS5433_PIN_DRV_FAST_SR1>;
	};

	spi4_cs: spi4-cs-pins {
		samsung,pins = "gpc4-3";
		samsung,pin-function = <EXYNOS_PIN_FUNC_OUTPUT>;
		samsung,pin-pud = <EXYNOS_PIN_PULL_UP>;
		samsung,pin-drv = <EXYNOS5433_PIN_DRV_FAST_SR1>;
	};

	spi4_cs_func: spi4-cs-func-pins {
		samsung,pins = "gpc4-3";
		samsung,pin-function = <EXYNOS_PIN_FUNC_3>;
		samsung,pin-pud = <EXYNOS_PIN_PULL_UP>;
		samsung,pin-drv = <EXYNOS5433_PIN_DRV_FAST_SR1>;
	};

	spi4_miso: spi4-miso-pins {
		samsung,pins = "gpc5-0";
		samsung,pin-function = <EXYNOS_PIN_FUNC_3>;
		samsung,pin-pud-pdn = <EXYNOS_PIN_PULL_NONE>;
		samsung,pin-pud = <EXYNOS_PIN_PULL_NONE>;
		samsung,pin-drv = <EXYNOS5433_PIN_DRV_FAST_SR4>;
	};

	spi4_mosi_sck_ssn: spi4-mosi-sck-ssn-pins {
		samsung,pins = "gpc5-1", "gpc4-2", "gpc4-3";
		samsung,pin-function = <EXYNOS_PIN_FUNC_3>;
		samsung,pin-pud = <EXYNOS_PIN_PULL_UP>;
		samsung,pin-drv = <EXYNOS5433_PIN_DRV_FAST_SR4>;
	};

	uart0_bus: uart0-bus-pins {
		samsung,pin-pud = <EXYNOS_PIN_PULL_NONE>;
		samsung,pins = "gpd2-3", "gpd2-2", "gpd2-1", "gpd2-0";
		samsung,pin-function = <EXYNOS_PIN_FUNC_2>;
	};

	uart1_bus: uart1-bus-pins {
		samsung,pin-pud = <EXYNOS_PIN_PULL_NONE>;
		samsung,pins = "gpb0-3", "gpb0-2", "gpb0-1", "gpb0-0";
		samsung,pin-function = <EXYNOS_PIN_FUNC_2>;
	};
};

&pinctrl_touch {
	gpc3: gpc3-gpio-bank {
		gpio-controller;
		#gpio-cells = <2>;

		interrupt-controller;
		#interrupt-cells = <2>;
	};

	i2c1_bus: i2c1-bus-pins {
		samsung,pins = "gpc3-1", "gpc3-0";
		samsung,pin-function = <EXYNOS_PIN_FUNC_2>;
		samsung,pin-pud = <EXYNOS_PIN_PULL_UP>;
		samsung,pin-drv = <EXYNOS5433_PIN_DRV_FAST_SR1>;
	};

	ese_cs_func: ese-cs-func-pins {
		samsung,pins = "gpc3-2";
		samsung,pin-function = <EXYNOS_PIN_FUNC_OUTPUT>;
		samsung,pin-pud = <EXYNOS_PIN_PULL_NONE>;
		samsung,pin-drv = <EXYNOS5433_PIN_DRV_FAST_SR1>;
		samsung,pin-val = <1>;
	};

	ese_cs_func_suspend: ese-cs-func-suspend-pins {
		samsung,pins = "gpc3-2";
		samsung,pin-function = <EXYNOS_PIN_FUNC_INPUT>;
		samsung,pin-pud = <EXYNOS_PIN_PULL_DOWN>;
		samsung,pin-drv = <EXYNOS5433_PIN_DRV_FAST_SR1>;
	};
};
